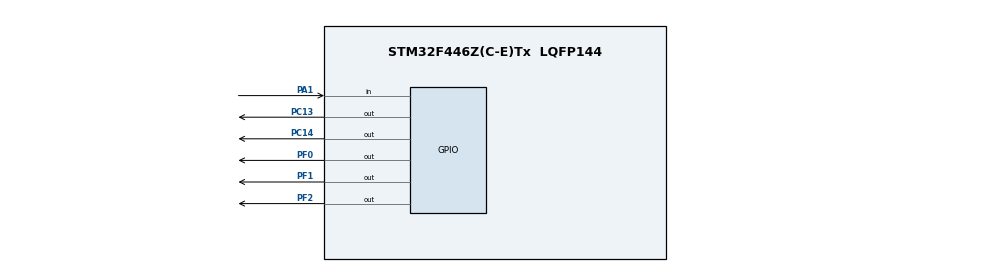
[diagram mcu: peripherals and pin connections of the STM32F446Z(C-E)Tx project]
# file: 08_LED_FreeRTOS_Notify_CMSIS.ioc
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FREERTOS.Tasks01=button,2,128,buttonControlTask,Default,NULL,Dynamic,NULL,NULL;led,2,128,leflashtask,Default,NULL,Dynamic,NULL,NULL
Mcu.Family=STM32F4
Mcu.Name=STM32F446Z(C-E)Tx
Mcu.Package=LQFP144
NVIC.PriorityGroup=NVIC_PRIORITYGROUP_4
PA1.Signal=GPIO_Input
PC13.Signal=GPIO_Output
PC14-OSC32_IN.Signal=GPIO_Output
PF0.Signal=GPIO_Output
PF1.Signal=GPIO_Output
PF2.Signal=GPIO_Output
ProjectManager.HeapSize=0x200
ProjectManager.StackSize=0x400
ProjectManager.TargetToolchain=STM32CubeIDE
RCC.CortexFreq_Value=16000000
RCC.USBFreq_Value=96000000
RCC.VCOOutputFreq_Value=192000000
VP_FREERTOS_VS_CMSIS_V1.Mode=CMSIS_V1
board=custom

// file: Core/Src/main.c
/* USER CODE BEGIN Header */
/**
  ******************************************************************************
  * @file           : main.c
  * @brief          : Main program body
  ******************************************************************************
  * @attention
  *
  * Copyright (c) 2024 STMicroelectronics.
  * All rights reserved.
  *
  * This software is licensed under terms that can be found in the LICENSE file
  * in the root directory of this software component.
  * If no LICENSE file comes with this software, it is provided AS-IS.
  *
  ******************************************************************************
  */
/* USER CODE END Header */
#include "main.h"
#include "cmsis_os.h"

/* USER CODE BEGIN Includes */
#include "FreeRTOS.h"
#include "task.h"
/* USER CODE END Includes */

//osThreadId buttonHandle;
//osThreadId ledHandle;
/* USER CODE BEGIN PV */
TaskHandle_t myButtonTaskHandle;
TaskHandle_t myLedTaskHandle;

uint32_t buttonCount = 0;
/* USER CODE END PV */

void SystemClock_Config(void);
static void MX_GPIO_Init(void);
void buttonControlTask(void const * argument);
void leflashtask(void const * argument);

int main(void)
{

  /* MCU Configuration--------------------------------------------------------*/

  /* Reset of all peripherals, Initializes the Flash interface and the Systick. */
  HAL_Init();

  /* Configure the system clock */
  SystemClock_Config();

  /* Initialize all configured peripherals */
  MX_GPIO_Init();

  /* Create the thread(s) */
  /* definition and creation of button */
//  osThreadDef(button, buttonControlTask, osPriorityHigh, 0, 128);
//  buttonHandle = osThreadCreate(osThread(button), NULL);

  /* definition and creation of led */
//  osThreadDef(led, leflashtask, osPriorityHigh, 0, 128);
//  ledHandle = osThreadCreate(osThread(led), NULL);

  xTaskCreate(buttonControlTask, "Button", 128, NULL, 2, &myButtonTaskHandle);
  xTaskCreate(leflashtask, "led control", 128, NULL, 2, &myLedTaskHandle);

  /* Start scheduler */
  //osKernelStart();

  vTaskStartScheduler();
  /* We should never get here as control is now taken by the scheduler */
  /* Infinite loop */
  while (1)
  {

  }
}

void SystemClock_Config(void)
{
  RCC_OscInitTypeDef RCC_OscInitStruct = {0};
  RCC_ClkInitTypeDef RCC_ClkInitStruct = {0};

  /** Configure the main internal regulator output voltage
  */
  __HAL_RCC_PWR_CLK_ENABLE();
  __HAL_PWR_VOLTAGESCALING_CONFIG(PWR_REGULATOR_VOLTAGE_SCALE3);

  /** Initializes the RCC Oscillators according to the specified parameters
  * in the RCC_OscInitTypeDef structure.
  */
  RCC_OscInitStruct.OscillatorType = RCC_OSCILLATORTYPE_HSI;
  RCC_OscInitStruct.HSIState = RCC_HSI_ON;
  RCC_OscInitStruct.HSICalibrationValue = RCC_HSICALIBRATION_DEFAULT;
  RCC_OscInitStruct.PLL.PLLState = RCC_PLL_NONE;
  if (HAL_RCC_OscConfig(&RCC_OscInitStruct) != HAL_OK)
  {
    Error_Handler();
  }

  /** Initializes the CPU, AHB and APB buses clocks
  */
  RCC_ClkInitStruct.ClockType = RCC_CLOCKTYPE_HCLK|RCC_CLOCKTYPE_SYSCLK
                              |RCC_CLOCKTYPE_PCLK1|RCC_CLOCKTYPE_PCLK2;
  RCC_ClkInitStruct.SYSCLKSource = RCC_SYSCLKSOURCE_HSI;
  RCC_ClkInitStruct.AHBCLKDivider = RCC_SYSCLK_DIV1;
  RCC_ClkInitStruct.APB1CLKDivider = RCC_HCLK_DIV1;
  RCC_ClkInitStruct.APB2CLKDivider = RCC_HCLK_DIV1;

  if (HAL_RCC_ClockConfig(&RCC_ClkInitStruct, FLASH_LATENCY_0) != HAL_OK)
  {
    Error_Handler();
  }
}

static void MX_GPIO_Init(void)
{
  GPIO_InitTypeDef GPIO_InitStruct = {0};

  /* GPIO Ports Clock Enable */
  __HAL_RCC_GPIOC_CLK_ENABLE();
  __HAL_RCC_GPIOF_CLK_ENABLE();
  __HAL_RCC_GPIOA_CLK_ENABLE();

  /*Configure GPIO pin Output Level */
  HAL_GPIO_WritePin(GPIOC, GPIO_PIN_13|GPIO_PIN_14, GPIO_PIN_RESET);

  /*Configure GPIO pin Output Level */
  HAL_GPIO_WritePin(GPIOF, GPIO_PIN_0|GPIO_PIN_1|GPIO_PIN_2, GPIO_PIN_RESET);

  /*Configure GPIO pins : PC13 PC14 */
  GPIO_InitStruct.Pin = GPIO_PIN_13|GPIO_PIN_14;
  GPIO_InitStruct.Mode = GPIO_MODE_OUTPUT_PP;
  GPIO_InitStruct.Pull = GPIO_NOPULL;
  GPIO_InitStruct.Speed = GPIO_SPEED_FREQ_LOW;
  HAL_GPIO_Init(GPIOC, &GPIO_InitStruct);

  /*Configure GPIO pins : PF0 PF1 PF2 */
  GPIO_InitStruct.Pin = GPIO_PIN_0|GPIO_PIN_1|GPIO_PIN_2;
  GPIO_InitStruct.Mode = GPIO_MODE_OUTPUT_PP;
  GPIO_InitStruct.Pull = GPIO_NOPULL;
  GPIO_InitStruct.Speed = GPIO_SPEED_FREQ_LOW;
  HAL_GPIO_Init(GPIOF, &GPIO_InitStruct);

  /*Configure GPIO pin : PA1 */
  GPIO_InitStruct.Pin = GPIO_PIN_1;
  GPIO_InitStruct.Mode = GPIO_MODE_INPUT;
  GPIO_InitStruct.Pull = GPIO_NOPULL;
  HAL_GPIO_Init(GPIOA, &GPIO_InitStruct);

}

void buttonControlTask(void const * argument)
{
  /* USER CODE BEGIN 5 */
  /* Infinite loop */
  for(;;)
  {

	  while(HAL_GPIO_ReadPin(GPIOA, GPIO_PIN_1) == GPIO_PIN_SET);
	    osSignalSet(myLedTaskHandle, 0x00);
	  //	  if(HAL_GPIO_ReadPin(GPIOA, GPIO_PIN_1) == GPIO_PIN_SET)
//	  {
//		  while(HAL_GPIO_ReadPin(GPIOA, GPIO_PIN_1) == GPIO_PIN_SET)
//		  xTaskNotify(myLedTaskHandle,0x00,eIncrement);
//	  }

  }
  /* USER CODE END 5 */
}

void leflashtask(void const * argument)
{
  /* USER CODE BEGIN leflashtask */
  /* Infinite loop */
	uint32_t pulNotificationValue = 0;
  for(;;)
  {
	  if(osSignalWait(&pulNotificationValue, 100).status == osEventSignal)
	  {
		  		  HAL_GPIO_TogglePin(GPIOF, GPIO_PIN_0 |GPIO_PIN_1 |GPIO_PIN_2);
		  		  HAL_GPIO_TogglePin(GPIOC, GPIO_PIN_13 | GPIO_PIN_14);
	  }

//	  if(xTaskNotifyWait(0, 0, &pulNotificationValue, portMAX_DELAY) == pdTRUE)//ilk parametre girşite bildirim değerini silmeye yarar ikinci parametre çıkışta bildirim değerini silmeye yarar
//	  {
//		  HAL_GPIO_TogglePin(GPIOF, GPIO_PIN_0 |GPIO_PIN_1 |GPIO_PIN_2);
//		  HAL_GPIO_TogglePin(GPIOC, GPIO_PIN_13 | GPIO_PIN_14);
//		  buttonCount = pulNotificationValue;
//		  vTaskDelay(100);
//	  }

  }
  /* USER CODE END leflashtask */
}

void Error_Handler(void)
{
  __disable_irq();
  while (1)
  {
  }
}
